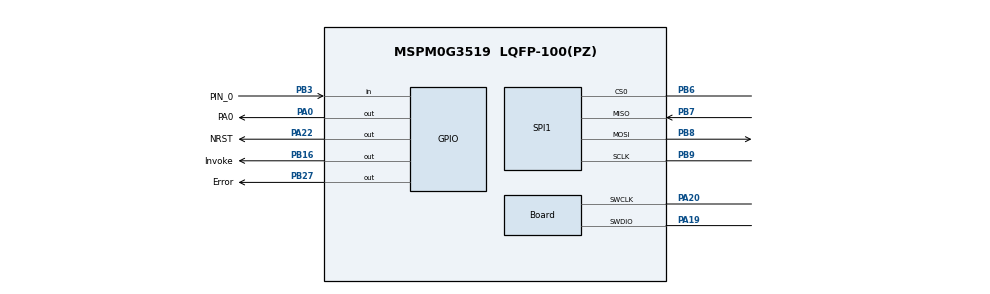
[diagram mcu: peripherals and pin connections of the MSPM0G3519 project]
// @cliArgs --device "MSPM0G351X" --package "LQFP-100(PZ)" --part "Default"
// @v2CliArgs --device "MSPM0G3519" --package "LQFP-100(PZ)"
// @cliArgs --board /ti/boards/LP_MSPM0G3519 --rtos nortos

/**
 * Import the modules used in this configuration.
 */
const GPIO   = scripting.addModule("/ti/driverlib/GPIO", {}, false);
const GPIO1  = GPIO.addInstance();
const GPIO2  = GPIO.addInstance();
const GPIO3  = GPIO.addInstance();
const SPI    = scripting.addModule("/ti/driverlib/SPI", {}, false);
const SPI1   = SPI.addInstance();
const SYSCTL = scripting.addModule("/ti/driverlib/SYSCTL");

/**
 * Write custom configuration values to the imported modules.
 */
GPIO1.$name                              = "GPIO_Button";
GPIO1.associatedPins[0].$name            = "PIN_0";
GPIO1.associatedPins[0].direction        = "INPUT";
GPIO1.associatedPins[0].assignedPort     = "PORTB";
GPIO1.associatedPins[0].internalResistor = "PULL_UP";
GPIO1.associatedPins[0].assignedPin      = "3";
GPIO1.associatedPins[0].pin.$assign      = "PB3";

const Board                       = scripting.addModule("/ti/driverlib/Board", {}, false);
Board.peripheral.$assign          = "DEBUGSS";
Board.peripheral.swclkPin.$assign = "PA20";
Board.peripheral.swdioPin.$assign = "PA19";

GPIO2.$name                          = "GPIO_BSL";
GPIO2.associatedPins.create(2);
GPIO2.associatedPins[0].$name        = "NRST";
GPIO2.associatedPins[0].initialValue = "SET";
GPIO2.associatedPins[0].assignedPort = "PORTA";
GPIO2.associatedPins[0].assignedPin  = "22";
GPIO2.associatedPins[0].pin.$assign  = "PA22";
GPIO2.associatedPins[1].$name        = "Invoke";
GPIO2.associatedPins[1].assignedPort = "PORTB";
GPIO2.associatedPins[1].assignedPin  = "16";
GPIO2.associatedPins[1].pin.$assign  = "PB16";

GPIO3.$name                          = "GPIO_LED";
GPIO3.associatedPins.create(2);
GPIO3.associatedPins[0].$name        = "Error";
GPIO3.associatedPins[0].assignedPort = "PORTB";
GPIO3.associatedPins[0].assignedPin  = "27";
GPIO3.associatedPins[0].pin.$assign  = "PB27";
GPIO3.associatedPins[1].$name        = "PA0";
GPIO3.associatedPins[1].initialValue = "SET";
GPIO3.associatedPins[1].assignedPort = "PORTA";
GPIO3.associatedPins[1].assignedPin  = "0";
GPIO3.associatedPins[1].pin.$assign  = "PA0";

SPI1.$name                      = "SPI_0";
SPI1.targetBitRate              = 1000000;
SPI1.rxFifoThreshold            = "DL_SPI_RX_FIFO_LEVEL_ONE_FRAME";
SPI1.txFifoThreshold            = "DL_SPI_TX_FIFO_LEVEL_ONE_FRAME";
SPI1.peripheral.$assign         = "SPI1";
SPI1.peripheral.sclkPin.$assign = "PB9";
SPI1.peripheral.mosiPin.$assign = "PB8";
SPI1.peripheral.misoPin.$assign = "PB7";
SPI1.peripheral.cs0Pin.$assign  = "PB6";

SYSCTL.peripheral.$assign = "SYSCTL";

const ProjectConfig              = scripting.addModule("/ti/project_config/ProjectConfig", {}, false);
ProjectConfig.migrationCondition = true;
